AUTOSAR XML (schema 4-3-0)
package /Mira_Project
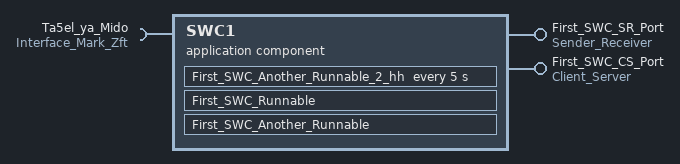
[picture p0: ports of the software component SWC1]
  application sw component type SWC1
    require port Ta5el_ya_Mido: nonqueued-receiver-com-spec=Mark_Zft1, required-interface=Interface_Mark_Zft
    provide port First_SWC_SR_Port: nonqueued-sender-com-spec=SR_DataElement, provided-interface=Sender_Receiver
    provide port First_SWC_CS_Port: server-com-spec=CS_Operation, provided-interface=Client_Server
    behavior First_SWC_InternalBehavior
      events:
        init event Init_Event: start-on-event=First_SWC_Runnable
        operation invoked event Operation_Event: start-on-event=First_SWC_Another_Runnable, operation=First_SWC_CS_Port.CS_Operation
        timing event Timing_Event: start-on-event=First_SWC_Another_Runnable_2_hh, period=5
      runnable First_SWC_Runnable: minimum-start-interval=0.05
      runnable First_SWC_Another_Runnable
      runnable First_SWC_Another_Runnable_2_hh
  swc implementation SWC1_Implementation: behavior=SWC1_InternalBehavior
